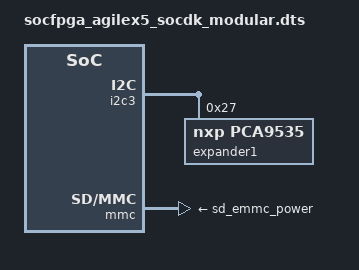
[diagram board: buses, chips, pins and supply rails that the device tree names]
// SPDX-License-Identifier:     GPL-2.0
/*
 * Copyright (C) 2026 Altera Corporation <www.altera.com>
 */

#include "socfpga_agilex5_socdk.dts"

&i2c3 {
	bootph-all;
	status = "okay";

	expander1: gpio@27 {
		compatible = "nxp,pca9535";
		reg = <0x27>;			/* SoM expander address */
		gpio-controller;
		#gpio-cells = <2>;
		bootph-all;
	};
};

&sd_emmc_power {
	bootph-all;
};

&sd_io_1v8_reg {
	gpios = <&expander1 1 GPIO_ACTIVE_HIGH>;
	bootph-all;
};

&mmc {
	status = "okay";

	no-mmc;
	disable-wp;
	cap-sd-highspeed;
	vmmc-supply = <&sd_emmc_power>;
	vqmmc-supply = <&sd_io_1v8_reg>;
	max-frequency = <200000000>;
	sdhci-caps = <0x00000000 0x0000c800>;

	/* SD card default speed (DS) and UHS-I SDR12 mode timing configuration */
	cdns,phy-dqs-timing-delay-sd-ds = <0x00780000>;
	cdns,phy-gate-lpbk-ctrl-delay-sd-ds = <0x81a40040>;
	cdns,phy-dll-slave-ctrl-sd-ds = <0x00a000fe>;
	cdns,phy-dq-timing-delay-sd-ds = <0x28000001>;

	/* SD card high speed and UHS-I SDR25 mode timing configuration */
	cdns,phy-dqs-timing-delay-sd-hs = <0x780001>;
	cdns,phy-gate-lpbk-ctrl-delay-sd-hs = <0x81a40040>;
	cdns,phy-dq-timing-delay-sd-hs = <0x10000001>;
	cdns,ctrl-hrs16-slave-ctrl-sd-hs = <0x101>;
	cdns,ctrl-hrs07-timing-delay-sd-hs = <0xA0001>;

	/* SD card UHS-I SDR50 mode timing configuration */
	cdns,phy-dqs-timing-delay-emmc-sdr = <0x780004>;
	cdns,phy-gate-lpbk-ctrl-delay-emmc-sdr = <0x80a40040>;
	cdns,phy-dll-slave-ctrl-emmc-sdr = <0x4000004>;
	cdns,phy-dq-timing-delay-emmc-sdr = <0x38000001>;
	cdns,ctrl-hrs09-timing-delay-emmc-sdr = <0xf1c1800c>;
	cdns,ctrl-hrs10-lpbk-ctrl-delay-emmc-sdr = <0x20000>;
	cdns,ctrl-hrs16-slave-ctrl-emmc-sdr = <0x101>;
	cdns,ctrl-hrs07-timing-delay-emmc-sdr = <0x90005>;

	/* SD card UHS-I SDR104 mode timing configuration */
	cdns,phy-dq-timing-delay-emmc-hs200 = <0x11000001>;
	cdns,phy-dqs-timing-delay-emmc-hs200 = <0x780004>;
	cdns,phy-dll-slave-ctrl-emmc-hs200 = <0x4d4d00>;
	cdns,phy-gate-lpbk-ctrl-delay-emmc-hs200 = <0x81a40040>;
	cdns,ctrl-hrs09-timing-delay-emmc-hs200 = <0xf1c18000>;
	cdns,ctrl-hrs10-lpbk-ctrl-delay-emmc-hs200 = <0x90000>;
	cdns,ctrl-hrs16-slave-ctrl-emmc-hs200 = <0x101>;
	cdns,ctrl-hrs07-timing-delay-emmc-hs200 = <0xa0001>;

	bootph-all;
};
